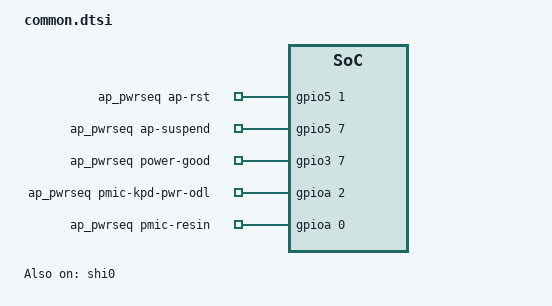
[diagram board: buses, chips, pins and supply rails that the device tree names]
/* Copyright 2022 The ChromiumOS Authors
 * Use of this source code is governed by a BSD-style license that can be
 * found in the LICENSE file.
 */

#include <dt-bindings/wake_mask_event_defines.h>

/ {
	chosen {
		cros,rtc = &mtc;
	};

	ec-console {
		compatible = "ec-console";
		disabled = "hostcmd";
	};

	ec-mkbp-host-event-wakeup-mask {
		compatible = "cros-ec,mkbp-host-event-wakeup-mask";
		wakeup-mask = <(
			HOST_EVENT_LID_OPEN |
			HOST_EVENT_POWER_BUTTON |
			HOST_EVENT_AC_CONNECTED |
			HOST_EVENT_AC_DISCONNECTED |
			HOST_EVENT_HANG_DETECT |
			HOST_EVENT_RTC |
			HOST_EVENT_MODE_CHANGE |
			HOST_EVENT_DEVICE)>;
	};

	ec-mkbp-event-wakeup-mask {
		compatible = "cros-ec,mkbp-event-wakeup-mask";
		wakeup-mask = <(MKBP_EVENT_KEY_MATRIX | \
				MKBP_EVENT_HOST_EVENT | \
				MKBP_EVENT_SENSOR_FIFO)>;
	};

	ap_pwrseq: ap-pwrseq {
		compatible = "cros-ec,qcom-ap-pwrseq";
		switchcap = <&switchcap>;
		ap-rst-gpios = <&gpio5 1 GPIO_ACTIVE_HIGH>;
		ap-suspend-gpios = <&gpio5 7 GPIO_ACTIVE_HIGH>;
		power-good-gpios = <&gpio3 7 GPIO_PULL_DOWN>;
		pmic-kpd-pwr-odl-gpios = <&gpioa 2 GPIO_OPEN_DRAIN>;
		pmic-resin-gpios = <&gpioa 0 GPIO_OPEN_DRAIN>;
	};
};

&shi0 {
	status = "okay";
	pinctrl-0 = <&shi_gp46_47_53_55>;
	pinctrl-1 = <&shi_gpio_gp46_47_53_55>;
	pinctrl-names = "default", "sleep";
};
